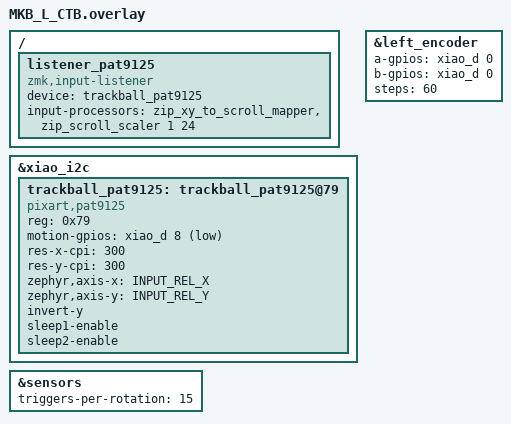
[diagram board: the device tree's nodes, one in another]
#include <zephyr/dt-bindings/input/input-event-codes.h>
#include <input/processors.dtsi>

&xiao_i2c {
    status = "okay";

    trackball_pat9125: trackball_pat9125@79 {
        status = "okay";
        compatible = "pixart,pat9125";
        reg = <0x79>;   // ID_SEL: HIGH=0x73, LOW=0x75, NC=0x79
        motion-gpios = <&xiao_d 8 (GPIO_ACTIVE_LOW | GPIO_PULL_UP)>;  // 要実測
        res-x-cpi = <300>;
        res-y-cpi = <300>;
        zephyr,axis-x = <INPUT_REL_X>;
        zephyr,axis-y = <INPUT_REL_Y>;
        // invert-x;
        invert-y;
        sleep1-enable;
        sleep2-enable;
    };
};

/* 左手はcentralなのでsplit不要、直接listen */
/ {
    listener_pat9125: listener_pat9125 {
        compatible = "zmk,input-listener";
        status = "okay";
        device = <&trackball_pat9125>;
        input-processors = <&zip_xy_to_scroll_mapper>, <&zip_scroll_scaler 1 24>;
    };
};

&left_encoder {
    a-gpios = <&xiao_d 0 GPIO_ACTIVE_HIGH>;
    b-gpios = <&xiao_d 0 GPIO_ACTIVE_HIGH>;
    steps = <60>;
    status = "okay";
};

&sensors {
    triggers-per-rotation = <15>;
};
